# DSS_CBUFF register map
Vendor: Texas Instruments
Peripheral module from a debugger description file (folder awr29xx).
Registers are 32-bit, read-write, no defined reset value unless marked. A register's access mark holds for its fields unless they carry their own. Offsets are as the file gives them; lines under a group give offsets from that group; [hi:lo] are bit positions; {n}, {i} and the like mark numbered series; 'fields as' and 'values as' point back to an identical list; <NAME> marks a mode.

## DSS_CBUFF
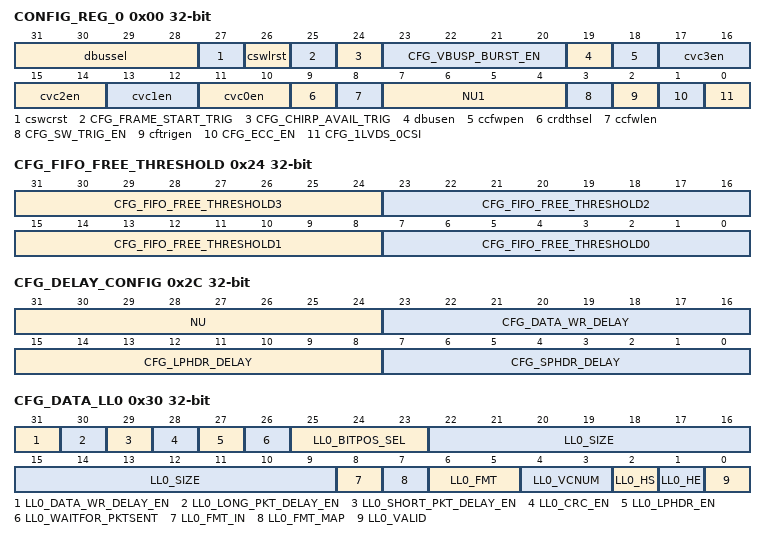
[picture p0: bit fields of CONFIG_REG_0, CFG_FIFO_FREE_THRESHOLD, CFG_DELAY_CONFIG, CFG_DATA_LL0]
0x00 CONFIG_REG_0 access not given — Basic Config register
  [31:28] dbussel rw — TI Internal feature. 1 : This selects the debug bus mode transmission on LVDS
  [27] cswcrst rw — CBUFF controller SW Reset 1 => RESET the CBUFF Controller 0 => RELEASE RESET for CBUFF Controller
  [26] cswlrst rw — TI Internal Feature. LVDS logic SW Reset. Debug feature. 1 => RESET the FSM 0 => RELEASE RESET
  [25] CFG_FRAME_START_TRIG — SW Trigger generation : Write 1 to this bit to generate a Frame Start SW Trigger
  [24] CFG_CHIRP_AVAIL_TRIG — SW Trigger generation : Write 1 to this bit to generate a Chirp Available SW Trigger
  [23:20] CFG_VBUSP_BURST_EN rw — TI Internal Feature. Only required for 900 Mbps 4 lane trasnmission CSI2 only Programming : 0xA : Burst Enable. Set this only for transmission at 900 Mbps Others : Burst disable.
  [19] dbusen rw — TC2 Mode selection. TI Internal feature. 0 : Normal 1 : When in TC2 mode, setting this bit will enable debug bus to sent via LVDS
  [18] ccfwpen rw — TI Internal Feature. Debug only. CSI2 only Programming : CFG_CSI2_FIFO_WORDS_PROCESSING_EN 0 : Use the fifo_free_words directly from CSI2 by vbusp_mstr to decide how many more words to send. 1 : Process the fifo_free_words and use it by vbusp_mstr to decide how many more words to send.
  [2n+11:2n+10] cvc{n}en rw (n=0..3) — CSI2 only Programming : 0 : No Vsync packet is sent at Frame boundary 1 : A VSYNC Start packet on Virtual Channel {n} is generated at beginning of Frame 2 : A VSYNC End packet on Virtual Channel {n} is generated at end of Frame 3 : A VSYNC Start packet on Virtual Channel {n} is generated at beginning of Frame and a VSYNC End packet on Virtual Channel {n} is generated at end of Frame
  [9] crdthsel rw — TI Internal Feature. Debug only. CSI2 only Programming : CFG_RDTHRESHOLD_SEL . This is a Debug feature. Not requred in Programming model 0 : The read threshold is selected based on the Write Side parsing engine 1 : The read threshold is selected based on the Read Side parsing engine.
  [8] ccfwlen rw — TI Internal Feature. Debug only. CSI2 only Programming : CFG_CSI2_FIFO_WORDS_LOAD_SW_EN. This is a Debug feature. Not requred in Programming model When CFG_CSI2_FIFO_WORDS_PROCESSING_EN==1 and CFG_CSI2_FIFO_WORDS_LOAD_SW_EN==1, then a fixed fifo_free_words from CSI2 is not used. Program the CFG_FIFO_FREE_THRESHOLD0 to 0x4
  [7:4] NU1 ro
  [3] CFG_SW_TRIG_EN rw — Select Chirp Available Trigger Source 0 : Chirp Available trigger will be generated by HW 1 : Chirp Available trigger will be generated by SW
  [2] cftrigen rw — Select Frame Start Trigger Source 0 : Frame trigger will be generated by HW 1 : Frame trigger will be generated by SW
  [1] CFG_ECC_EN rw — 0 : Disable ECC on the CBUF FIFO 1 : Enable ECC on the CBUF FIFO
  [0] CFG_1LVDS_0CSI rw — 0 : Send data over CSI-2 1 : Send data over LVDS
0x04 CFG_SPHDR_ADDRESS — Short Packet Header Address
  [31:0] CFG_SPHDR_ADDRESS — CSI2 Programming : Configure the CSI_PROTOCOL_ENGINE__CSI_VC_SHORT_PACKET_HEADER Address in the CSI Protocol Engine LVDS Programming : Configure with the static value : 0x55555555
0x08 CFG_CMD_HSVAL — HSYNC Value
  [31:0] CFG_CMD_HSVAL — CSI2 Programming : Configure the HSync Start Short Packet Value LVDS Programming : If LVDS CRC is enabled : Configure with the static value : 0x55555555 If LVDS CRC is disbaled : Configure with the static value : 0xAAAAAAAA
0x0C CFG_CMD_HEVAL — HEND Value
  [31:0] CFG_CMD_HEVAL — CSI2 Programming : Configure the HSync End Short Packet Value LVDS Programming : If LVDS CRC is enabled : Configure with the static value : 0x33333333 If LVDS CRC is disbaled : Configure with the static value : 0xAAAAAAAA
0x10 CFG_CMD_VSVAL — VSYNC Value
  [31:0] CFG_CMD_VSVAL — CSI2 Programming : Configure the VSync Start Short Packet Value LVDS Programming : Configure with the static value : 0xAAAAAAAA
0x14 CFG_CMD_VEVAL — VEND Value
  [31:0] CFG_CMD_VEVAL — CSI2 Programming : Configure the VSync End Short Packet Value LVDS Programming : Configure with the static value : 0xAAAAAAAA
0x18 CFG_LPHDR_ADDRESS — Long Packet Address
  [31:0] CFG_LPHDR_ADDRESS — CSI2 Programming : Configure the CSI_PROTOCOL_ENGINE__CSI_VC_LONG_PACKET_HEADER Address in the CSI Protocol Engine LVDS Programming : Configure with the static value : 0x55555555
0x20 CFG_CHIRPS_PER_FRAME — Number of Chirps per Frame
  [31:0] CFG_CHIRPS_PER_FRAME — Configure the number of Chirps in a Frame
0x24 CFG_FIFO_FREE_THRESHOLD — CSI2 FIFO threshold for transferring data from CBUFF to CSI2
  [31:24] CFG_FIFO_FREE_THRESHOLD3 — TI Internal Feature CSI2 only Programming : Configure the threshold used to fill the FIFO3 in the CSI Protocol engine. CBUFF will send data to the Protocol Engine only if there is a larger number of Free slots that that configured in this register. By default, only 1 FIFO will be used so register programming is not Required in Programming model
  [23:16] CFG_FIFO_FREE_THRESHOLD2 — TI Internal Feature CSI2 only Programming : Configure the threshold used to fill the FIFO2 in the CSI Protocol engine. CBUFF will send data to the Protocol Engine only if there is a larger number of Free slots that that configured in this register. By default, only 1 FIFO will be used so register programming is not Required in Programming model
  [15:8] CFG_FIFO_FREE_THRESHOLD1 — TI Internal Feature CSI2 only Programming : Configure the threshold used to fill the FIFO1 in the CSI Protocol engine. CBUFF will send data to the Protocol Engine only if there is a larger number of Free slots that that configured in this register. By default, only 1 FIFO will be used so register programming is not Required in Programming model
  [7:0] CFG_FIFO_FREE_THRESHOLD0 — CSI2 only Programming : Configure the threshold used to fill the FIFO0 in the CSI Protocol engine. CBUFF will send data to the Protocol Engine only if there is a larger number of Free slots that that configured in this register
0x28 CFG_LPPYLD_ADDRESS — Long payload Address
  [31:0] CFG_LPPYLD_ADDRESS — CSI2 only Programming : Configure the CSI_PROTOCOL_ENGINE__CSI_VC_LONG_PACKET_PAYLOAD Address in the CSI Protocol Engine
0x2C CFG_DELAY_CONFIG access per field — Delay Config Registers
  [31:24] NU ro
  [23:16] CFG_DATA_WR_DELAY rw — TI Internal Feature CSI2 only Programming : Configure an additional delay after sending a Long packet Payload. This is a Debug feature. Not requred in Programming model
  [15:8] CFG_LPHDR_DELAY rw — TI Internal Feature CSI2 only Programming : Configure an additional delay after sending a Long packet Header. This is a Debug feature. Not requred in Programming model
  [7:0] CFG_SPHDR_DELAY rw — TI Internal Feature CSI2 only Programming : Configure an additional delay after sending a Short packet. This is a Debug feature. Not requred in Programming model
0x30 CFG_DATA_LL0 — Payload Description : Linked list entry 0
  [31] LL0_DATA_WR_DELAY_EN — TI Internal Feature CSI2 only Programming : Use the Packet Delay configured in CFG_DELAY_CONFIG. This is a Debug feature. Not requred in Programming model
  [30] LL0_LONG_PKT_DELAY_EN — TI Internal Feature CSI2 only Programming : Use the Packet Delay configured in CFG_DELAY_CONFIG. This is a Debug feature. Not requred in Programming model
  [29] LL0_SHORT_PKT_DELAY_EN — TI Internal Feature CSI2 only Programming : Use the Packet Delay configured in CFG_DELAY_CONFIG. This is a Debug feature. Not requred in Programming model
  [28] LL0_CRC_EN — 0 : CRC is disbaled 1 : This linklist corresponds to ADC Buffer data. Enable the CRC check from ADC Buffer to CBUFF
  [27] LL0_LPHDR_EN — CSI2 Programming : 1 : Entry is start of a new CSI-2 packet. Send the LP Payload Header before sending data corresponind to this Linklist 0 : Link list is not the start of a Long packet but part of previous packet and hence directly send data LVDS Programming : 1 : Entry is start of a new LVDS Frame 0 : Entry is not the start of the new LVDS Frame
  [26] LL0_WAITFOR_PKTSENT — TI Internal Feature Reserved for furture debug enhancement 1 : Wait for packet sent signal ack from CSI2 to move forward 0 : Do not wait for packet sent
  [25:23] LL0_BITPOS_SEL — TI Internal Feature. Reserved for future use to select which of the 12-bits or 14-bits to be picked up from 16-bit CBUFF unit
  [22:9] LL0_SIZE — Configure the Size of the data in terms of the numer of samples (not in terms of number of bytes). Sample refers to a 16 bit CBUFF Unit
  [8] LL0_FMT_IN — 0 : The incoming data sources for this Linklist is aligned to 128-bit 1 : The incoming data sources for this Linklist is aligned to 96-bit
  [7] LL0_FMT_MAP — LVDS only : 0 : Choose CFG_LVDS_MAPPING_LANEx_FMT_0_y 1 : Choose CFG_LVDS_MAPPING_LANEx_FMT_1_y
  [6:5] LL0_FMT — Specify the LVDS/CSI2 output format. 00 - 16bit 01 - 14-bit 10 - 12-bit
  [4:3] LL0_VCNUM — CSI-2 : Configure the Virtual Channel Number for the Long Packet over which this data is sent
  [2] LL0_HS — CSI-2 : 0 : Do not send an Hsync Start packet before sending this data 1 : Send an Hsync Start Packet before sending this data LVDS : 0 : Entry is not the first data of LVDS Frame 1 : Entry is the first data in the LVDS Frame
  [1] LL0_HE — CSI-2 : 0 : Do not send an Hsync End packet after sending this data 1 : Send an Hsync End Packet after sending this data LVDS : 0 : Entry is not the last data of LVDS Frame 1 : Entry is the last data in the LVDS Frame
  [0] LL0_VALID — 0 : Linklist entry is invalid 1 : Linklist entry is valid
0x34 CFG_DATA_LL0_LPHDR_VAL — Payload Description : Linked list entry 0
  [31:0] LL0_LPHDR_VAL — CSI-2 Programming : Configure the Long Packet Header to be sent to the Protocol Engine if the LPHDR_EN field is set for the linklist. LVDS Programming : Configure with the static value : 0xBBBBBBBB
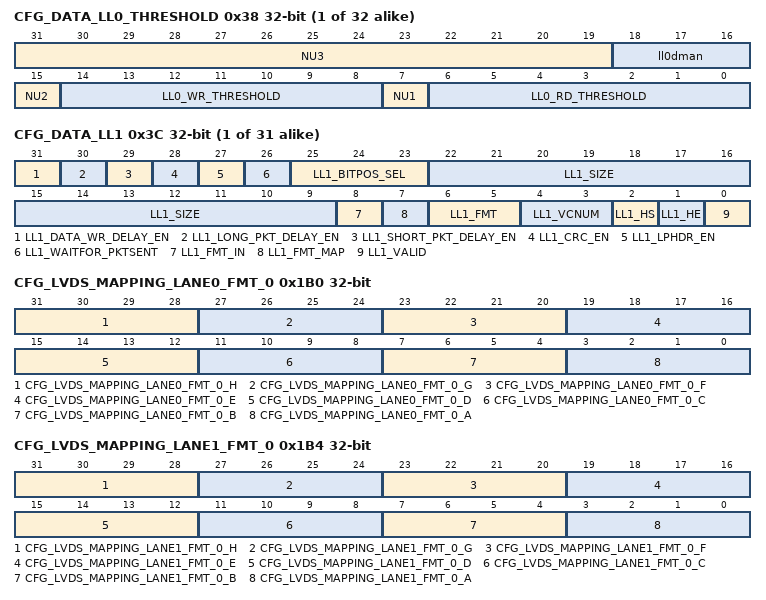
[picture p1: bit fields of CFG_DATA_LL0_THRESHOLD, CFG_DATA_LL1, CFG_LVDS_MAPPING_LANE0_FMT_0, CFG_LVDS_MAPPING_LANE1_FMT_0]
{0x38+0xC*i} CFG_DATA_LL{i}_THRESHOLD access per field (i=0..31)
  [31:19] NU3 ro
  [18:16] ll{i}dman rw — If the long Packet Header is enabled, CBUFF can generate a DMA request to trigger the DMA trasnfer for the new packet 0 : Send a Request on DMA HW Req output line 0 1 : Send a Request on DMA HW Req output line 1 2 : Send a Request on DMA HW Req output line 2 3 : Send a Request on DMA HW Req output line 3 4 : Send a Request on DMA HW Req output line 4 5 : Send a Request on DMA HW Req output line 5 6 : Send a Request on DMA HW Req output line 6 7 : Do not generate dma trigger
  [15] NU2 ro
  [14:8] LL{i}_WR_THRESHOLD rw — Configure the CBUFF FIFO Write threshold over which CBUFF will stall the DMA write to the CBUFF. Static configuration. This can be programmed to fixed value mentioned in the Programming Model
  [7] NU1 ro
  [6:0] LL{i}_RD_THRESHOLD rw — Configure the CBUFF Read threshold to be Reached before sending the data over CSI2/LVDS and start draining the CBUFF FIFO. Static configuration. This can be programmed to fixed value mentioned in the Programming Model
{0x30+0xC*i} CFG_DATA_LL{i} (i=1..31)
  [31] LL{i}_DATA_WR_DELAY_EN — TI Internal Feature CSI2 only Programming : Use the Packet Delay configured in CFG_DELAY_CONFIG. This is a Debug feature. Not requred in Programming model
  [30] LL{i}_LONG_PKT_DELAY_EN — TI Internal Feature CSI2 only Programming : Use the Packet Delay configured in CFG_DELAY_CONFIG. This is a Debug feature. Not requred in Programming model
  [29] LL{i}_SHORT_PKT_DELAY_EN — TI Internal Feature CSI2 only Programming : Use the Packet Delay configured in CFG_DELAY_CONFIG. This is a Debug feature. Not requred in Programming model
  [28] LL{i}_CRC_EN — 0 : CRC is disbaled 1 : This linklist corresponds to ADC Buffer data. Enable the CRC check from ADC Buffer to CBUFF
  [27] LL{i}_LPHDR_EN — CSI2 Programming : 1 : Entry is start of a new CSI-2 packet. Send the LP Payload Header before sending data corresponind to this Linklist 0 : Link list is not the start of a Long packet but part of previous packet and hence directly send data LVDS Programming : 1 : Entry is start of a new LVDS Frame 0 : Entry is not the start of the new LVDS Frame
  [26] LL{i}_WAITFOR_PKTSENT — TI Internal Feature Reserved for furture debug enhancement 1 : Wait for packet sent signal ack from CSI2 to move forward 0 : Do not wait for packet sent
  [25:23] LL{i}_BITPOS_SEL — TI Internal Feature. Reserved for future use to select which of the 12-bits or 14-bits to be picked up from 16-bit CBUFF unit
  [22:9] LL{i}_SIZE — Configure the Size of the data in terms of the numer of samples (not in terms of number of bytes). Sample refers to a 16 bit CBUFF Unit
  [8] LL{i}_FMT_IN — 0 : The incoming data sources for this Linklist is aligned to 128-bit 1 : The incoming data sources for this Linklist is aligned to 96-bit
  [7] LL{i}_FMT_MAP — LVDS only : 0 : Choose CFG_LVDS_MAPPING_LANEx_FMT_0_y 1 : Choose CFG_LVDS_MAPPING_LANEx_FMT_1_y
  [6:5] LL{i}_FMT — Specify the LVDS/CSI2 output format. 00 - 16bit 01 - 14-bit 10 - 12-bit
  [4:3] LL{i}_VCNUM — CSI-2 : Configure the Virtual Channel Number for the Long Packet over which this data is sent
  [2] LL{i}_HS — CSI-2 : 0 : Do not send an Hsync Start packet before sending this data 1 : Send an Hsync Start Packet before sending this data LVDS : 0 : Entry is not the first data of LVDS Frame 1 : Entry is the first data in the LVDS Frame
  [1] LL{i}_HE — CSI-2 : 0 : Do not send an Hsync End packet after sending this data 1 : Send an Hsync End Packet after sending this data LVDS : 0 : Entry is not the last data of LVDS Frame 1 : Entry is the last data in the LVDS Frame
  [0] LL{i}_VALID — 0 : Linklist entry is invalid 1 : Linklist entry is valid
{0x34+0xC*i} CFG_DATA_LL{i}_LPHDR_VAL (i=1..31)
  [31:0] LL{i}_LPHDR_VAL — CSI-2 Programming : Configure the Long Packet Header to be sent to the Protocol Engine if the LPHDR_EN field is set for the linklist. LVDS Programming : Configure with the static value : 0xBBBBBBBB
0x1B0 CFG_LVDS_MAPPING_LANE0_FMT_0
  [31:28] CFG_LVDS_MAPPING_LANE0_FMT_0_H — Lane 0 mapping if Format 0 is selected. Bit [2:0] : 0-7 : Selects the CBUFF unit from the 8 CBUFF units to be sent on Lane 0 Bit 3 0 : Entry is not valid 1 : Entry is valid Please refer to LVDS Mapping Format in Programming model for more details
  [27:24] CFG_LVDS_MAPPING_LANE0_FMT_0_G — Lane 0 mapping if Format 0 is selected. Bit [2:0] : 0-7 : Selects the CBUFF unit from the 8 CBUFF units to be sent on Lane 0 Bit 3 0 : Entry is not valid 1 : Entry is valid Please refer to LVDS Mapping Format in Programming model for more details
  [23:20] CFG_LVDS_MAPPING_LANE0_FMT_0_F — Lane 0 mapping if Format 0 is selected. Bit [2:0] : 0-7 : Selects the CBUFF unit from the 8 CBUFF units to be sent on Lane 0 Bit 3 0 : Entry is not valid 1 : Entry is valid Please refer to LVDS Mapping Format in Programming model for more details
  [19:16] CFG_LVDS_MAPPING_LANE0_FMT_0_E — Lane 0 mapping if Format 0 is selected. Bit [2:0] : 0-7 : Selects the CBUFF unit from the 8 CBUFF units to be sent on Lane 0 Bit 3 0 : Entry is not valid 1 : Entry is valid Please refer to LVDS Mapping Format in Programming model for more details
  [15:12] CFG_LVDS_MAPPING_LANE0_FMT_0_D — Lane 0 mapping if Format 0 is selected. Bit [2:0] : 0-7 : Selects the CBUFF unit from the 8 CBUFF units to be sent on Lane 0 Bit 3 0 : Entry is not valid 1 : Entry is valid Please refer to LVDS Mapping Format in Programming model for more details
  [11:8] CFG_LVDS_MAPPING_LANE0_FMT_0_C — Lane 0 mapping if Format 0 is selected. Bit [2:0] : 0-7 : Selects the CBUFF unit from the 8 CBUFF units to be sent on Lane 0 Bit 3 0 : Entry is not valid 1 : Entry is valid Please refer to LVDS Mapping Format in Programming model for more details
  [7:4] CFG_LVDS_MAPPING_LANE0_FMT_0_B — Lane 0 mapping if Format 0 is selected. Bit [2:0] : 0-7 : Selects the CBUFF unit from the 8 CBUFF units to be sent on Lane 0 Bit 3 0 : Entry is not valid 1 : Entry is valid Please refer to LVDS Mapping Format in Programming model for more details
  [3:0] CFG_LVDS_MAPPING_LANE0_FMT_0_A — Lane 0 mapping if Format 0 is selected. Bit [2:0] : 0-7 : Selects the CBUFF unit from the 8 CBUFF units to be sent on Lane 0 Bit 3 0 : Entry is not valid 1 : Entry is valid Please refer to LVDS Mapping Format in Programming model for more details
0x1B4 CFG_LVDS_MAPPING_LANE1_FMT_0
  [31:28] CFG_LVDS_MAPPING_LANE1_FMT_0_H — Lane 1 mapping if Format 0 is selected. Bit [2:0] : 0-7 : Selects the CBUFF unit from the 8 CBUFF units to be sent on Lane 1 Bit 3 0 : Entry is not valid 1 : Entry is valid Please refer to LVDS Mapping Format in Programming model for more details
  [27:24] CFG_LVDS_MAPPING_LANE1_FMT_0_G — Lane 1 mapping if Format 0 is selected. Bit [2:0] : 0-7 : Selects the CBUFF unit from the 8 CBUFF units to be sent on Lane 1 Bit 3 0 : Entry is not valid 1 : Entry is valid Please refer to LVDS Mapping Format in Programming model for more details
  [23:20] CFG_LVDS_MAPPING_LANE1_FMT_0_F — Lane 1 mapping if Format 0 is selected. Bit [2:0] : 0-7 : Selects the CBUFF unit from the 8 CBUFF units to be sent on Lane 1 Bit 3 0 : Entry is not valid 1 : Entry is valid Please refer to LVDS Mapping Format in Programming model for more details
  [19:16] CFG_LVDS_MAPPING_LANE1_FMT_0_E — Lane 1 mapping if Format 0 is selected. Bit [2:0] : 0-7 : Selects the CBUFF unit from the 8 CBUFF units to be sent on Lane 1 Bit 3 0 : Entry is not valid 1 : Entry is valid Please refer to LVDS Mapping Format in Programming model for more details
  [15:12] CFG_LVDS_MAPPING_LANE1_FMT_0_D — Lane 1 mapping if Format 0 is selected. Bit [2:0] : 0-7 : Selects the CBUFF unit from the 8 CBUFF units to be sent on Lane 1 Bit 3 0 : Entry is not valid 1 : Entry is valid Please refer to LVDS Mapping Format in Programming model for more details
  [11:8] CFG_LVDS_MAPPING_LANE1_FMT_0_C — Lane 1 mapping if Format 0 is selected. Bit [2:0] : 0-7 : Selects the CBUFF unit from the 8 CBUFF units to be sent on Lane 1 Bit 3 0 : Entry is not valid 1 : Entry is valid Please refer to LVDS Mapping Format in Programming model for more details
  [7:4] CFG_LVDS_MAPPING_LANE1_FMT_0_B — Lane 1 mapping if Format 0 is selected. Bit [2:0] : 0-7 : Selects the CBUFF unit from the 8 CBUFF units to be sent on Lane 1 Bit 3 0 : Entry is not valid 1 : Entry is valid Please refer to LVDS Mapping Format in Programming model for more details
  [3:0] CFG_LVDS_MAPPING_LANE1_FMT_0_A — Lane 1 mapping if Format 0 is selected. Bit [2:0] : 0-7 : Selects the CBUFF unit from the 8 CBUFF units to be sent on Lane 1 Bit 3 0 : Entry is not valid 1 : Entry is valid Please refer to LVDS Mapping Format in Programming model for more details
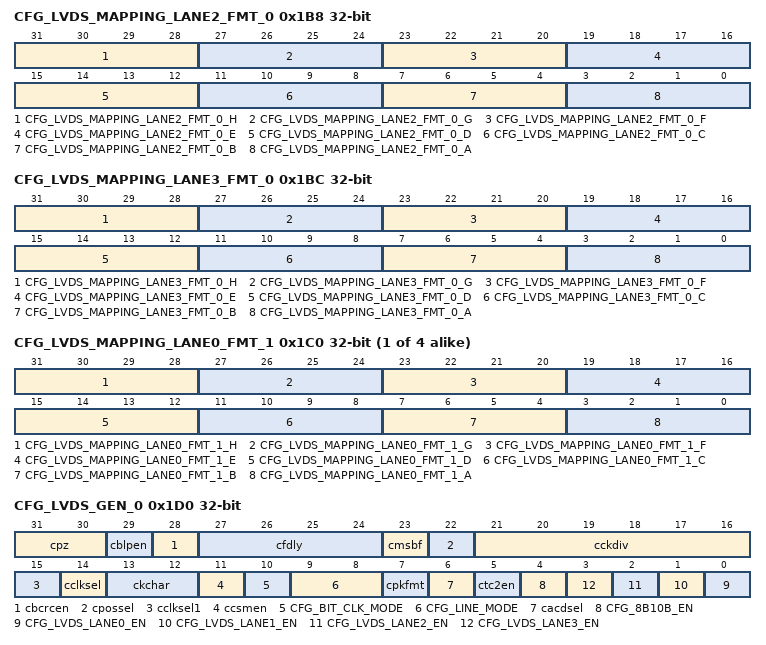
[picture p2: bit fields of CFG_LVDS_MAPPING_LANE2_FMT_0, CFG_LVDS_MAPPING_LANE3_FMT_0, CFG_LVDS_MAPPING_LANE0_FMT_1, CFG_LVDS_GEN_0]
0x1B8 CFG_LVDS_MAPPING_LANE2_FMT_0
  [31:28] CFG_LVDS_MAPPING_LANE2_FMT_0_H — Please refer to LVDS Mapping Format section for confiuration details
  [27:24] CFG_LVDS_MAPPING_LANE2_FMT_0_G — Please refer to LVDS Mapping Format section for confiuration details
  [23:20] CFG_LVDS_MAPPING_LANE2_FMT_0_F — Please refer to LVDS Mapping Format section for confiuration details
  [19:16] CFG_LVDS_MAPPING_LANE2_FMT_0_E — Please refer to LVDS Mapping Format section for confiuration details
  [15:12] CFG_LVDS_MAPPING_LANE2_FMT_0_D — Please refer to LVDS Mapping Format section for confiuration details
  [11:8] CFG_LVDS_MAPPING_LANE2_FMT_0_C — Please refer to LVDS Mapping Format section for confiuration details
  [7:4] CFG_LVDS_MAPPING_LANE2_FMT_0_B — Please refer to LVDS Mapping Format section for confiuration details
  [3:0] CFG_LVDS_MAPPING_LANE2_FMT_0_A — Please refer to LVDS Mapping Format section for confiuration details
0x1BC CFG_LVDS_MAPPING_LANE3_FMT_0
  [31:28] CFG_LVDS_MAPPING_LANE3_FMT_0_H — Please refer to LVDS Mapping Format section for confiuration details
  [27:24] CFG_LVDS_MAPPING_LANE3_FMT_0_G — Please refer to LVDS Mapping Format section for confiuration details
  [23:20] CFG_LVDS_MAPPING_LANE3_FMT_0_F — Please refer to LVDS Mapping Format section for confiuration details
  [19:16] CFG_LVDS_MAPPING_LANE3_FMT_0_E — Please refer to LVDS Mapping Format section for confiuration details
  [15:12] CFG_LVDS_MAPPING_LANE3_FMT_0_D — Please refer to LVDS Mapping Format section for confiuration details
  [11:8] CFG_LVDS_MAPPING_LANE3_FMT_0_C — Please refer to LVDS Mapping Format section for confiuration details
  [7:4] CFG_LVDS_MAPPING_LANE3_FMT_0_B — Please refer to LVDS Mapping Format section for confiuration details
  [3:0] CFG_LVDS_MAPPING_LANE3_FMT_0_A — Please refer to LVDS Mapping Format section for confiuration details
{0x1C0+4i} CFG_LVDS_MAPPING_LANE{i}_FMT_1 (i=0..3)
  [31:28] CFG_LVDS_MAPPING_LANE{i}_FMT_1_H — Please refer to LVDS Mapping Format section for confiuration details
  [27:24] CFG_LVDS_MAPPING_LANE{i}_FMT_1_G — Please refer to LVDS Mapping Format section for confiuration details
  [23:20] CFG_LVDS_MAPPING_LANE{i}_FMT_1_F — Please refer to LVDS Mapping Format section for confiuration details
  [19:16] CFG_LVDS_MAPPING_LANE{i}_FMT_1_E — Please refer to LVDS Mapping Format section for confiuration details
  [15:12] CFG_LVDS_MAPPING_LANE{i}_FMT_1_D — Please refer to LVDS Mapping Format section for confiuration details
  [11:8] CFG_LVDS_MAPPING_LANE{i}_FMT_1_C — Please refer to LVDS Mapping Format section for confiuration details
  [7:4] CFG_LVDS_MAPPING_LANE{i}_FMT_1_B — Please refer to LVDS Mapping Format section for confiuration details
  [3:0] CFG_LVDS_MAPPING_LANE{i}_FMT_1_A — Please refer to LVDS Mapping Format section for confiuration details
0x1D0 CFG_LVDS_GEN_0
  [31:30] cpz — LVDS Clock config. 1 : Clock alignment enabled Others : Internal clock alignment not enabled This needs to be set to 0x1 for correct functionality
  [29] cblpen — TI Internal CFG_LASTPULSE_EN
  [28] cbcrcen — LVDS Frame CRC 0 : CRC is not sent at the end of LVDS Frame 1 : CRC is sent at the end of the LVDS Frame
  [27:24] cfdly — LVDS FIFO Initial Threshold. This is a Static configuration and sould be set to a fixed value as mention in the Programming model
  [23] cmsbf — 1 : Data is sent out on the LVDS lane MSB first 0 : Data is sent out on the LVDS lane LSB first
  [22] cpossel — 0 : When a new chirp is starting, align first sample start to negedge of DDR clock. 1 : When a new chirp is starting, align first sample start to posedge of DDR clock (recommended)
  [21:16] cckdiv — TI Internal feature. CFG_LVDS_CLK_DIV
  [15] cclksel1 — TRM Description : 0 : DDR mode clock mux 1 : SDR mode clock mux TI Restricted Description : CFG_LVDS_CLK_SEL1 0-> Use div-by-2 (Q2 path ) 1 -> Used for direct (Q1 path)
  [14] cclksel — TI Internal feature. CFG_LVDS_CLK_SEL (between div-by-N and CLK_HSI_DIG) 1 -> CLK_HSI_DIG; 0 - through div-by-N (N is programmed in CFG_LVDS_CLK_DIV)
  [13:12] ckchar — TI Internal feature. CFG_K_CHAR_SEL
  [11] ccsmen — TRM Description : As per alignment TI Restricted Description : 0 : Regular operation 1 : Continuous Streaming Mode Enabled (Not supported internally also in AR16xx)
  [10] CFG_BIT_CLK_MODE — Bit Clock Mode 0 : SDR clocking mode 1 : DDR clocking mode
  [9:8] CFG_LINE_MODE — TI Internal feature. Reserved.
  [7] cpkfmt — TI Internal feature. CFG_PACK_FORMAT: While packing in 12/14 bit whether to use CSI like packing or general packing.
  [6] cacdsel — TI Internal feature. CFG_ALL_CHL_READY_DELAY_SEL This bit is added to take of the fast to slow transition in the ADC Buffer. 0 => If the LVDS clock frequency (SDR) is >= 200MHz 1 => If the LVDS clock frequency (SDR) is < 200MHz
  [5] ctc2en — TI Internal feature. 0 : Regular operation 1: TC2MODE Enable (Not supported internally also in AR16xx)
  [4] CFG_8B10B_EN — TI Internal Feature. Reserved. For Furture enhancement. Not supported in this version 0 : No encoding 1: 8B10B encoding
  [n] CFG_LVDS_LANE{n}_EN (n=0..3) — LVDS only programming : 0 : LVDS Lane {n} is disbaled 1 : LVDS Lane {n} is enabled
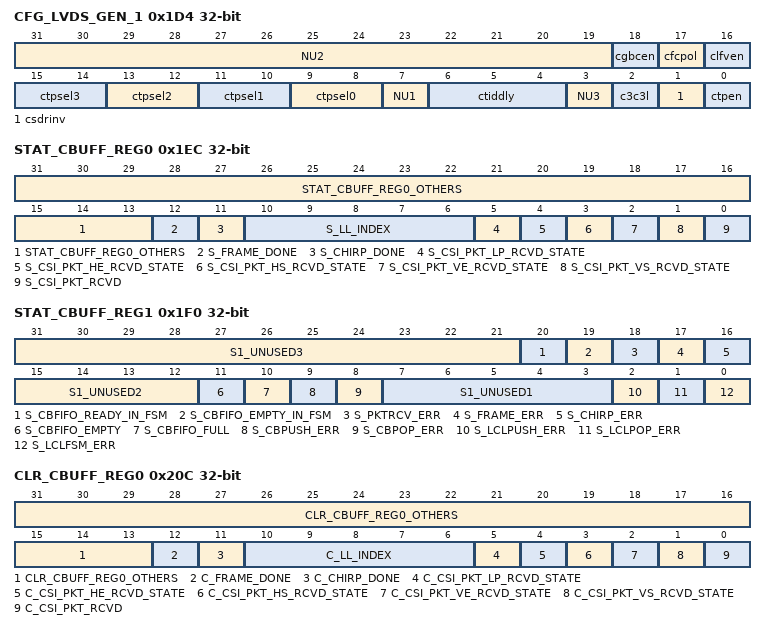
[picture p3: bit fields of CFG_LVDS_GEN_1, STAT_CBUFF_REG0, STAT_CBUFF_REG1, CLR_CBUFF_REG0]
0x1D4 CFG_LVDS_GEN_1 access per field
  [31:19] NU2 ro — RESERVED
  [18] cgbcen rw — TI Internal Feature. 0 : Bit clk is free running 1 : Bit clk is valid only during the valid frame.
  [17] cfcpol rw — TI Internal Feature. 0 : During IDLE, Frame clock will be 0. Start of the valid sample is indicated by the rise edge 1 : During IDLE. Frame clock will be 1. Start of the valid sample is indicated by the fall edge.
  [16] clfven rw — TI Internal feature. Extend the Single Ended Frame Valid When the frame_valid is used as a single ended signal, then make this 1. 0 : Regular Operation. Frame Valid will exactly match with the valid data. 1 : The frame_valid would start early by about 10 lvds_clk (internal) and would extend beyond by 10 lvds_clk (internal) after the end of the frame
  [2n+9:2n+8] ctpsel{n} rw (n=0..3) — TI Internal feature. This is used when Test Pattern Generation Enabled is enabled. 0 :Incremental pattern - For Lane {n}
  [7] NU1 ro — RESERVED
  [6:4] ctiddly rw — TI Internal feature. Configure the skew delay in terms on number of cycles
  [3] NU3 ro
  [2] c3c3l rw — LVDS Only Programming: 0 : Regular Operation 1 : Enable 3Ch-3Lane mode in LVDS. Refer to Programming model for more details
  [1] csdrinv rw — TI Internal feature. Configure the clock inversion during SDR mode. 0 : No inversion 1 : Inversion
  [0] ctpen rw — TI Internal feature. 0 : Regular Operation 1 : LVDS Testpattern Enable
0x1D8 CFG_LVDS_GEN_2
  [31:0] CFG_LVDS_GEN_2 — CFG_LVDS_GEN_2[0]: Configure LSB/MSB first for CRC. This feature is supported only when the field CFG_LVDS_GEN_0[28] is set to 1 0 -> The calculated value of 32-bit Ethernet polynomial CRC is swapped and sent out, clear this bit if data is set to LSB first (CFG_LVDS_GEN_0[23]=0) but CRC should be MSB first or vice-versa 1 -> The calculated value of 32-bit Ethernet polynomial CRC is sent out without swapping, set this bit if both data and CRC should have same format (LSB/MSB first) CFG_LVDS_GEN_2[1]: Configure value of frame clock during inter frame period 0 -> Frame clock is held low 1 -> Frame clock is held high CFG_LVDS_GEN_2[2]: Configure frame clock period. This feature is supported only when the field CFG_LVDS_GEN_0[28] is set to 1 0 -> 32-bit CRC is transmitted as single packet with frame clock set to 16h16l (16 high 16 low) configuration 1 -> 32-bit CRC is transmitted as two packets with frame clock set to 8h8l (8 high 8 low) configuration for each packet CFG_LVDS_GEN_2[3]: Configure bit clock during inter frame period 0 -> Bit clock toggles during inter frame period 1 -> Bit clock does not toggle during inter frame period, the value of bit clock is held low This feature is supported when DDR clock is selected (CFG_LVDS_GEN_0[10]=1) and first data sample is driven on posedge of DDR clock (CFG_LVDS_GEN_0[22]=1) CFG_LVDS_GEN_2[4]: Configure CRC inversion. This feature is supported only when the field CFG_LVDS_GEN_0[28] is set to 1 0 -> The calculated value of 32-bit Ethernet polynomial CRC is inverted and sent out 1 -> The calculated value of 32-bit Ethernet polynomial CRC is sent out without inversion CFG_LVDS_GEN_2[5]: Enable/disable the calibration mode, in this mode frame clock will follow data lane[0] 0 -> Calibration mode is disabled 1 -> Calibration mode is enabled
0x1DC CFG_MASK_REG0
  [31:0] CFG_MASK_REG0 — Mask Register field corresponding to STAT_CBUFF_REG0. Refer STAT_CBUFF_REG0 for bitwise mapping. 0 : Event is unmasked and will cause an interrupt on occuruence 1 : Event is masked. No interrupt will be generated on occurrence
0x1E0 CFG_MASK_REG1
  [31:0] CFG_MASK_REG1 — Mask Register field corresponding to STAT_CBUFF_REG1. Refer STAT_CBUFF_REG1 for bitwise mapping. 0 : Event is unmasked and will cause an interrupt on occuruence 1 : Event is masked. No interrupt will be generated on occurrence
0x1E4 CFG_MASK_REG2
  [31:0] CFG_MASK_REG2 — Mask Register field corresponding to STAT_LVDS_REG0. Refer STAT_LVDS_REG0 for bitwise mapping. 0 : Event is unmasked and will cause an interrupt on occuruence 1 : Event is masked. No interrupt will be generated on occurrence
0x1E8 CFG_MASK_REG3
  [31:0] CFG_MASK_REG3 — RESERVED
0x1EC STAT_CBUFF_REG0 ro
  [31:13] STAT_CBUFF_REG0_OTHERS — Reseved for future enhancement
  [12] S_FRAME_DONE — Indicates that CBUFF has completed sending out data for the current Frame
  [11] S_CHIRP_DONE — Indicates that CBUFF has completed sending out data for the current Chirp
  [10:6] S_LL_INDEX — TI Internal Feature. Debug only. Current Linked list index.
  [5] S_CSI_PKT_LP_RCVD_STATE — TI Internal Feature Indicates that the CSI-2 Packet Received is sent to the CBUFF from the Protocol Engine after Long Data Packet
  [4] S_CSI_PKT_HE_RCVD_STATE — TI Internal Feature Indicates that the CSI-2 Packet Received is sent to the CBUFF from the Protocol Engine after Hsync End Packet
  [3] S_CSI_PKT_HS_RCVD_STATE — TI Internal Feature Indicates that the CSI-2 Packet Received is sent to the CBUFF from the Protocol Engine after Hsync Start Packet
  [2] S_CSI_PKT_VE_RCVD_STATE — TI Internal Feature Indicates that the CSI-2 Packet Received is sent to the CBUFF from the Protocol Engine after Vsync End Packet
  [1] S_CSI_PKT_VS_RCVD_STATE — TI Internal Feature Indicates that the CSI-2 Packet Received is sent to the CBUFF from the Protocol Engine after Vsync Start Packet
  [0] S_CSI_PKT_RCVD — TI Internal Feature Indicates that the CSI-2 Packet Received is sent to the CBUFF from the Protocol Engine
0x1F0 STAT_CBUFF_REG1 ro
  [31:21] S1_UNUSED3
  [20] S_CBFIFO_READY_IN_FSM — TI Internal Feature. Debug only. cbuff-fifo_ready - Keep this masked. Not relevant.
  [19] S_CBFIFO_EMPTY_IN_FSM — TI Internal Feature. Debug only. cbuff-fifo_empty - Keep this masked. Not relevant.
  [18] S_PKTRCV_ERR — TI Internal Feature. Debug only. If the packetReceived arrives at a wrong time. It should NOT be coming while in IDLE state (as no packet was sent before) and in HIBER state (where the next LL group is being evaluated).
  [17] S_FRAME_ERR — Indicates the FrameStart arrived before CBUFF has completed sending out data for all the Chirps programmed
  [16] S_CHIRP_ERR — Indicates tha the chirpAvailable from ADCBuffer arrived before CBUFF has completed sending out the previous Chirp data.
  [15:12] S1_UNUSED2 — RESERVED
  [11] S_CBFIFO_EMPTY — TI Internal Feature. Debug only. CBUFF_FIFO Empty Status – Keep this masked, since full and empty will be normal conditions.
  [10] S_CBFIFO_FULL — TI Internal Feature. Debug only. CBUFF_FIFO Full Status – Keep this masked, since full and empty will be normal conditions.
  [9] S_CBPUSH_ERR — TI Internal Feature. Debug only. CBUFF_FIFO_PUSH_ERROR
  [8] S_CBPOP_ERR — TI Internal Feature. Debug only. CBUFF_FIFO_POP_ERROR
  [7:3] S1_UNUSED1 — RESERVED
  [2] S_LCLPUSH_ERR — TI Internal Feature. Debug only. LCL_FIFO_PUSH_ERROR
  [1] S_LCLPOP_ERR — TI Internal Feature. Debug only. LCL_FIFO_POP_ERROR
  [0] S_LCLFSM_ERR — TI Internal Feature. Debug only. LCL_FIFO_FSM_ERROR
0x1F4 STAT_CBUFF_REG2 ro
  [31:0] STAT_CBUFF_REG2 — RESERVED. This does not have coresponding clear or mask
0x1F8 STAT_CBUFF_REG3 ro
  [31:0] STAT_CBUFF_REG3 — RESERVED. This does not have coresponding clear or mask
0x1FC STAT_LVDS_REG0 ro
  [31:0] STAT_LVDS_REG0 — TI Internal Feature. Debug only. Clr is CLR_LVDS_REG0 and MASK is CFG_MASK_REG2 FSM_STAT_CODE: [3:0] is for Ch0, [7:4] is for Ch1, [11:8] is for Ch2, [15:12] is for ch3 ASYNC_FIFO_STATUS: [19:16] is for Ch0, [23:20] is for Ch1, [27:24] is for Ch2, [32:28] is for ch3 FSM_STATE_CODE : Using this the states can be decoded. ASYNC_FIFO_STATUS: 0 - POP_ERROR; 1 - PUSH_ERROR; 2- POP_EMPTY; 3 - PUSH_FULL. Set the mask for POP_EMPTY and PUSH_FULL. These are normal conditions and will keep happening and need not generate any interrupt
{0x1FC+4i} STAT_LVDS_REG{i} ro (i=1..3)
  [31:0] STAT_LVDS_REG{i} — RESERVED
0x20C CLR_CBUFF_REG0 access not given
  [31:13] CLR_CBUFF_REG0_OTHERS — TI Internal Feature.Clear Register field corresponding to STAT_CBUFF_REG0. Write 0x1 to Clear the field
  [12] C_FRAME_DONE — Clear Register field corresponding to STAT_CBUFF_REG0. Write 0x1 to Clear the field
  [11] C_CHIRP_DONE — Clear Register field corresponding to STAT_CBUFF_REG0. Write 0x1 to Clear the field
  [10:6] C_LL_INDEX — TI Internal Feature.Clear Register field corresponding to STAT_CBUFF_REG0. Write 0x1 to Clear the field
  [5] C_CSI_PKT_LP_RCVD_STATE — TI Internal Feature.Clear Register field corresponding to STAT_CBUFF_REG0. Write 0x1 to Clear the field
  [4] C_CSI_PKT_HE_RCVD_STATE — TI Internal Feature.Clear Register field corresponding to STAT_CBUFF_REG0. Write 0x1 to Clear the field
  [3] C_CSI_PKT_HS_RCVD_STATE — TI Internal Feature.Clear Register field corresponding to STAT_CBUFF_REG0. Write 0x1 to Clear the field
  [2] C_CSI_PKT_VE_RCVD_STATE — TI Internal Feature.Clear Register field corresponding to STAT_CBUFF_REG0. Write 0x1 to Clear the field
  [1] C_CSI_PKT_VS_RCVD_STATE — TI Internal Feature.Clear Register field corresponding to STAT_CBUFF_REG0. Write 0x1 to Clear the field
  [0] C_CSI_PKT_RCVD — TI Internal Feature. Clear Register field corresponding to STAT_CBUFF_REG0. Write 0x1 to Clear the field
0x210 CLR_CBUFF_REG1 access not given
  [31:0] CLR_CBUFF_REG1 — TI Internal Feature.Clear Register field corresponding to STAT_CBUFF_REG1. Write 0x1 to Clear the field
0x214 CLR_LVDS_REG0 access not given
  [31:0] CLR_LVDS_REG0 — TI Internal Feature.Clear Register field corresponding to STAT_LVDS_REG0. Write 0x1 to Clear the field
0x218 CLR_LVDS_REG1 access not given
  [31:0] CLR_LVDS_REG1 — RESERVED
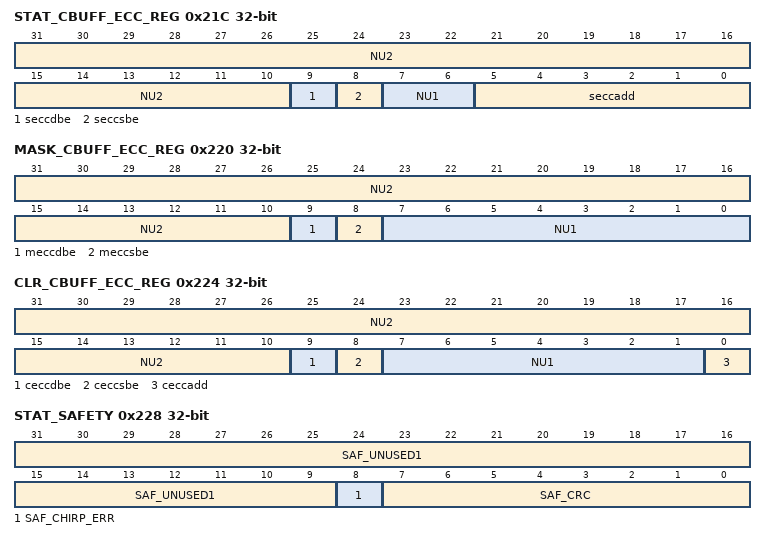
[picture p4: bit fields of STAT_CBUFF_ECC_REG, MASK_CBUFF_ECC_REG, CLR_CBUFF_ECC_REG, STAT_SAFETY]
0x21C STAT_CBUFF_ECC_REG ro
  [31:10] NU2
  [9] seccdbe — 0 : No Double bit error 1 : Indicates a double bit error has occurred
  [8] seccsbe — 0 : No Single bit error 1 : Indicates a single bit error has occurred
  [7:6] NU1
  [5:0] seccadd — 6-bit address where the ECC error occurred. It is valid when either seccsbe or seccdbe is set. If none of them is set, then the addr does not mean anything.
0x220 MASK_CBUFF_ECC_REG access per field
  [31:10] NU2 ro
  [9] meccdbe rw — 0 : Double bit error indications are unmasked 1 : Double bit error indications are Masked
  [8] meccsbe rw — 0 : Single bit error indications are unmasked 1 : Single bit error indications are Masked
  [7:0] NU1 ro
0x224 CLR_CBUFF_ECC_REG access not given
  [31:10] NU2 ro
  [9] ceccdbe — Clear Register field corresponding to STAT_CBUFF_ECC. Write 0x1 to Clear the field
  [8] ceccsbe — Clear Register field corresponding to STAT_CBUFF_ECC. Write 0x1 to Clear the field
  [7:1] NU1 ro
  [0] ceccadd — Clear Register field corresponding to STAT_CBUFF_ECC. Write 0x1 to Clear the field
0x228 STAT_SAFETY ro
  [31:9] SAF_UNUSED1 — RESERVED
  [8] SAF_CHIRP_ERR — Safety Error. Indicates tha the chirpAvailable from ADCBuffer arrived before CBUFF has completed sending out the previous Chirp data.
  [7:0] SAF_CRC — TRM Desccription : Indicates a CRC error between ADCBuffer and CBUFF. 0 : No Error Non Zero : Error TI Restricted Description : 0 - CRC for col-0 - [15:0], 1 - CRC for col-1 [31:16]; 2 - CRC for col-2 [47:32]; 3 - CRC for col-3 [63:48] 4 - CRC for col-4 - [79:64]; 5 - CRC for col-5 [95:80]; 6 - CRC for col-6 [111 :96 ; 7 - for col-7 [127:112]
0x22C MASK_SAFETY
  [31:0] MASK_SAFETY — Mask Register field corresponding to STAT_SAFETY. Refer STAT_SAFETY for bitwise mapping. 0 : Event is unmasked and will cause an interrupt on occuruence 1 : Event is masked. No interrupt will be generated on occurrence
0x230 CLR_SAFETY access not given
  [31:0] CLR_SAFETY — Clear Register field corresponding to STAT_SAFETY. Write 0x1 to Clear the field
